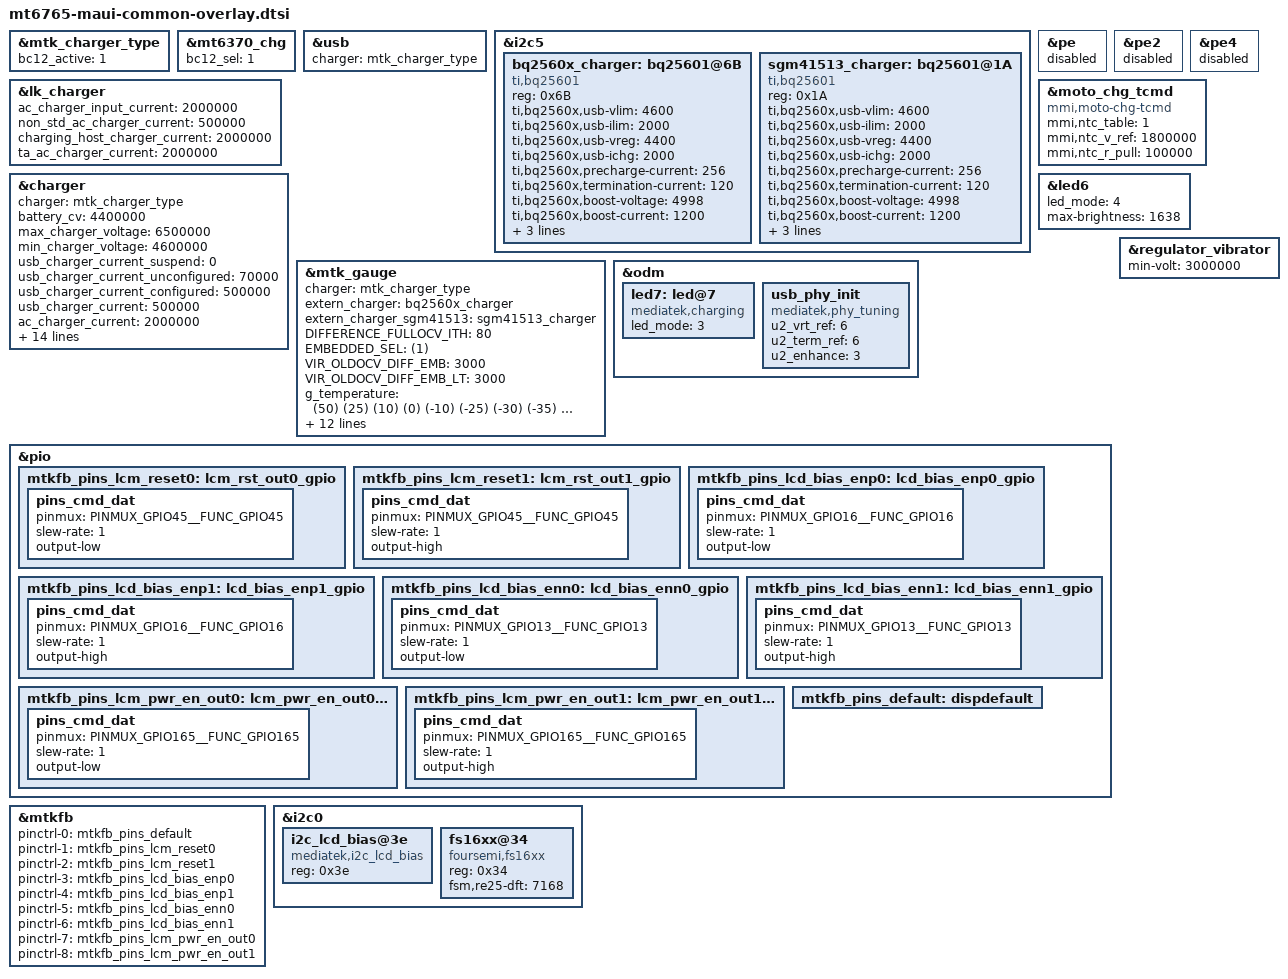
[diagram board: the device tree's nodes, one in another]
/* Copyright (c) 2022, Motorola Mobility Inc. All rights reserved.
 *
 * This program is free software; you can redistribute it and/or modify
 * it under the terms of the GNU General Public License version 2 and
 * only version 2 as published by the Free Software Foundation.
 *
 * This program is distributed in the hope that it will be useful,
 * but WITHOUT ANY WARRANTY; without even the implied warranty of
 * MERCHANTABILITY or FITNESS FOR A PARTICULAR PURPOSE.  See the
 * GNU General Public License for more details.
 */

#include "mediatek/mt6765-moto-common-overlay.dtsi"
#include "mediatek/mt6765-moto-common-irtx.dtsi"
#include "mediatek/mt6765-moto-maui-fps.dtsi"
#include "mediatek/mt6765-maui-camera-sensor-overlay.dtsi"
#include "mediatek/cust_mt6765_touch_maui_720x1600.dtsi"

#include <dt-bindings/iio/mt635x-auxadc.h>

&mtk_charger_type {
	bc12_active = <1>;
};

&mt6370_chg {
	bc12_sel = <1>;
};

&usb {
	charger = <&mtk_charger_type>;
};

&i2c5 {
	bq2560x_charger:bq25601@6B {
		compatible = "ti,bq25601";
		reg = <0x6B>;
		ti,bq2560x,usb-vlim = <4600>;
		ti,bq2560x,usb-ilim = <2000>;
		ti,bq2560x,usb-vreg = <4400>;
		ti,bq2560x,usb-ichg = <2000>;
		ti,bq2560x,precharge-current = <256>;
		ti,bq2560x,termination-current = <120>;
		ti,bq2560x,boost-voltage = <4998>;
		ti,bq2560x,boost-current = <1200>;
		ti,bq2560x,enable_term;
		ti,bq2560x,stat-pin-ctrl = <3>;
		ti,bq2560x,vac-ovp-threshold = <6500>;

	};

	sgm41513_charger:bq25601@1A {
		compatible = "ti,bq25601";
		reg = <0x1A>;
		ti,bq2560x,usb-vlim = <4600>;
		ti,bq2560x,usb-ilim = <2000>;
		ti,bq2560x,usb-vreg = <4400>;
		ti,bq2560x,usb-ichg = <2000>;
		ti,bq2560x,precharge-current = <256>;
		ti,bq2560x,termination-current = <120>;
		ti,bq2560x,boost-voltage = <4998>;
		ti,bq2560x,boost-current = <1200>;
		ti,bq2560x,enable_term;
		ti,bq2560x,stat-pin-ctrl = <3>;
		ti,bq2560x,vac-ovp-threshold = <6500>;
	};
};

&lk_charger {
	ac_charger_input_current = <2000000>;
	non_std_ac_charger_current = <500000>;
	charging_host_charger_current = <2000000>;
	ta_ac_charger_current = <2000000>;
};

&pe {
	status = "disable";
};
&pe2 {
	status = "disable";
};
&pe4 {
	status = "disable";
};

&charger {
	charger = <&mtk_charger_type>;
	/* common */
	battery_cv = <4400000>;
	max_charger_voltage = <6500000>;
	min_charger_voltage = <4600000>;

	/* charging current */
	usb_charger_current_suspend = <0>;
	usb_charger_current_unconfigured = <70000>;
	usb_charger_current_configured = <500000>;
	usb_charger_current = <500000>;
	ac_charger_current = <2000000>;
	ac_charger_input_current = <2000000>;
	non_std_ac_charger_current = <1000000>;
	charging_host_charger_current = <1500000>;
	apple_1_0a_charger_current = <650000>;
	apple_2_1a_charger_current = <800000>;
	ta_ac_charger_current = <2000000>;
	typec_limit_aicr = <3000000>;

	/*mmi config*/
	mmi,iterm-ma = <150>;
	mmi,mmi-temp-zones = <0 4200 1000 0>,
			<15 0 1000 1000>,
			<45 0 3000 3000>,
			<60 4200 2500 0>;
	mmi,enable-charging-limit;
	mmi,upper-limit-capacity = <65>;
	mmi,lower-limit-capacity = <60>;
};

&mtk_gauge {
	charger = <&mtk_charger_type>;
	extern_charger = <&bq2560x_charger>;
	extern_charger_sgm41513 = <&sgm41513_charger>;
	DIFFERENCE_FULLOCV_ITH = <80>;  /*gauge cut-off current, should overtop ieoc 50ma*/
	EMBEDDED_SEL = <(1)>;  /*embedded battery,don't remove the battery for user*/
	VIR_OLDOCV_DIFF_EMB = <3000>; /*0.1mv*/
	VIR_OLDOCV_DIFF_EMB_LT = <3000>; /*0.1mv*/

	/* battery prop */
	g_temperature = <(50) (25) (10) (0) (-10) (-25) (-30) (-35) (-40) (-45)>;
	g_FG_PSEUDO100 = <98 98 100 100
		98 98 100 100
		98 98 100 100
		98 98 100 100
		98 98 100 100
		100 100 100 100
		100 100 100 100
		100 100 100 100
		100 100 100 100
		100 100 100 100>;

	g_Q_MAX = <4822 4871 2490 1965
		4856 4936 2468 1984
		4854 4905 2310 1946
		4725 4794 1858 1873
		4856 4920 1843 1851
		2211 1652 1533 1541
		2201 1642 1523 1531
		2191 1632 1513 1521
		2181 1622 1503 1511
		2171 1612 1493 1501>;

	g_Q_MAX_H_CURRENT = <4822 4871 2190 1665
		4856 4936 2168 1684
		4854 4905 2010 1646
		4725 4794 1558 1573
		4856 4920 1543 1551
		2210 1650 1533 1541
		2200 1640 1523 1531
		2190 1630 1513 1521
		2180 1620 1503 1511
		2170 1610 1493 1501>;
	ACTIVE_TABLE = <(5)>;

	/* adc channels */
	io-channels = <&pmic_auxadc AUXADC_BAT_TEMP>,
			<&pmic_auxadc AUXADC_BATADC>,
			<&pmic_auxadc AUXADC_VBIF>,
			<&pmic_auxadc AUXADC_IMP>;
	io-channel-names = "pmic_battery_temp",
			"pmic_battery_voltage",
			"pmic_bif_voltage",
			"pmic_ptim_voltage";

	df-serialnum = "SB18C98449";
	#include "mediatek/bat_setting/SWD_4V4_5000MAH.dtsi"
	#include "mediatek/bat_setting/ATL_4V4_5000MAH.dtsi"
};

&moto_chg_tcmd {
                compatible = "mmi,moto-chg-tcmd";
                status = "okay";

                mmi,ntc_table = <1>;
                mmi,ntc_v_ref = <1800000>;
                mmi,ntc_r_pull = <100000>;
};

&led6 {
	led_mode = <4>;
	max-brightness = <1638>; /*2047*0.8*/
};

&odm {
	led7:led@7 {
		compatible = "mediatek,charging";
		led_mode = <3>;
	};

	usb_phy_init:usb_phy_init {
		compatible = "mediatek,phy_tuning";
		u2_vrt_ref = <6>;
		u2_term_ref = <6>;
		u2_enhance = <3>;
		status = "okay";
	};
};

&pio {
	mtkfb_pins_lcm_reset0: lcm_rst_out0_gpio {
		pins_cmd_dat {
			pinmux = <PINMUX_GPIO45__FUNC_GPIO45>;
			slew-rate = <1>;
			output-low;
		};
	};

	mtkfb_pins_lcm_reset1: lcm_rst_out1_gpio {
		pins_cmd_dat {
			pinmux = <PINMUX_GPIO45__FUNC_GPIO45>;
			slew-rate = <1>;
			output-high;
		};
	};

	mtkfb_pins_lcd_bias_enp0: lcd_bias_enp0_gpio {
		pins_cmd_dat {
			pinmux = <PINMUX_GPIO16__FUNC_GPIO16>;
			slew-rate = <1>;
			output-low;
		};
	};

	mtkfb_pins_lcd_bias_enp1: lcd_bias_enp1_gpio {
		pins_cmd_dat {
			pinmux = <PINMUX_GPIO16__FUNC_GPIO16>;
			slew-rate = <1>;
			output-high;
		};
	};

	mtkfb_pins_lcd_bias_enn0: lcd_bias_enn0_gpio {
		pins_cmd_dat {
			pinmux = <PINMUX_GPIO13__FUNC_GPIO13>;
			slew-rate = <1>;
			output-low;
		};
	};

	mtkfb_pins_lcd_bias_enn1: lcd_bias_enn1_gpio {
		pins_cmd_dat {
			pinmux = <PINMUX_GPIO13__FUNC_GPIO13>;
			slew-rate = <1>;
			output-high;
		};
	};

	mtkfb_pins_lcm_pwr_en_out0: lcm_pwr_en_out0_gpio {
		pins_cmd_dat {
			pinmux = <PINMUX_GPIO165__FUNC_GPIO165>;
			slew-rate = <1>;
			output-low;
		};
	};

	mtkfb_pins_lcm_pwr_en_out1: lcm_pwr_en_out1_gpio {
		pins_cmd_dat {
			pinmux = <PINMUX_GPIO165__FUNC_GPIO165>;
			slew-rate = <1>;
			output-high;
		};
	};

	mtkfb_pins_default: dispdefault {
	};
};

&mtkfb {
	pinctrl-names = "dispdefault", "lcm_rst_out0_gpio", "lcm_rst_out1_gpio",
			"lcd_bias_enp0_gpio", "lcd_bias_enp1_gpio",
			"lcd_bias_enn0_gpio", "lcd_bias_enn1_gpio",
			"lcm_pwr_en_out0_gpio", "lcm_pwr_en_out1_gpio";
	pinctrl-0 = <&mtkfb_pins_default>;
	pinctrl-1 = <&mtkfb_pins_lcm_reset0>;
	pinctrl-2 = <&mtkfb_pins_lcm_reset1>;
	pinctrl-3 = <&mtkfb_pins_lcd_bias_enp0>;
	pinctrl-4 = <&mtkfb_pins_lcd_bias_enp1>;
	pinctrl-5 = <&mtkfb_pins_lcd_bias_enn0>;
	pinctrl-6 = <&mtkfb_pins_lcd_bias_enn1>;
	pinctrl-7 = <&mtkfb_pins_lcm_pwr_en_out0>;
	pinctrl-8 = <&mtkfb_pins_lcm_pwr_en_out1>;
	status = "okay";
};

&i2c0 {
	i2c_lcd_bias@3e {
		compatible = "mediatek,i2c_lcd_bias";
		reg = <0x3e>;
		status = "okay";
	};

	fs16xx@34 {
		compatible = "foursemi,fs16xx";
		reg = <0x34>;
		fsm,re25-dft = <7168>;
		status = "okay";
	};
};

&regulator_vibrator {
	min-volt = <3000000>;
};
